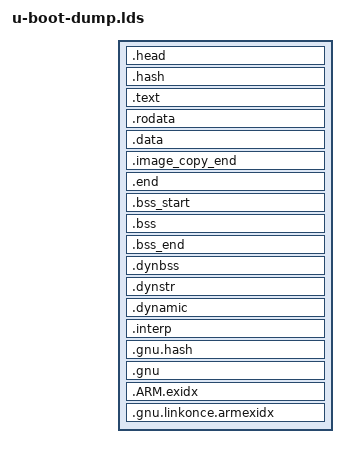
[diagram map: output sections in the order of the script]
/*
 * Copyright (c) 2004-2008 Texas Instruments
 *
 * (C) Copyright 2002
 * Gary Jennejohn, DENX Software Engineering, <garyj@denx.de>
 *
 * SPDX-License-Identifier:	GPL-2.0+
 */

OUTPUT_FORMAT("elf32-littlearm", "elf32-littlearm", "elf32-littlearm")
OUTPUT_ARCH(arm)
ENTRY(_start)
SECTIONS
{
	. = 0x4A000000;
	. = ALIGN(4);
	.head  . :
	{
		*(.__image_copy_start)
		dump_test/spare_head.o (.data*)
	}
	
        .hash . :
        {
		dump_test/uboot_hash.o(.data*)
        }

	. = ALIGN(4);
	.text :
	{
		*(.vectors)
		dump_test/start.o (.text*)
		*(.text*)
	}

	. = ALIGN(4);
	.rodata : { *(SORT_BY_ALIGNMENT(SORT_BY_NAME(.rodata*))) }

	. = ALIGN(4);
	.data : {
		*(.data*)
	}

	. = ALIGN(4);

	. = .;
		
	. = ALIGN(4);

	.image_copy_end :
	{
		*(.__image_copy_end)
	}

	.end :
	{
		*(.__end)
	}

	_image_binary_end = .;

/*
 * Compiler-generated __bss_start and __bss_end, see arch/arm/lib/bss.c
 * __bss_base and __bss_limit are for linker only (overlay ordering)
 */

	.bss_start (OVERLAY) : {
		KEEP(*(.__bss_start));
		__bss_base = .;
	}

	.bss __bss_base (OVERLAY) : {
		*(.bss*)
		 . = ALIGN(4);
		 __bss_limit = .;
	}

	.bss_end __bss_limit (OVERLAY) : {
		KEEP(*(.__bss_end));
	}
	
	.dynbss : { *(.dynbss) }
	.dynstr : { *(.dynstr*) }
	.dynamic : { *(.dynamic*) }	
	.interp : { *(.interp*) }
	.gnu.hash : { *(.gnu.hash) }
	.gnu : { *(.gnu*) }
	.ARM.exidx : { *(.ARM.exidx*) }
	.gnu.linkonce.armexidx : { *(.gnu.linkonce.armexidx.*) }
}
